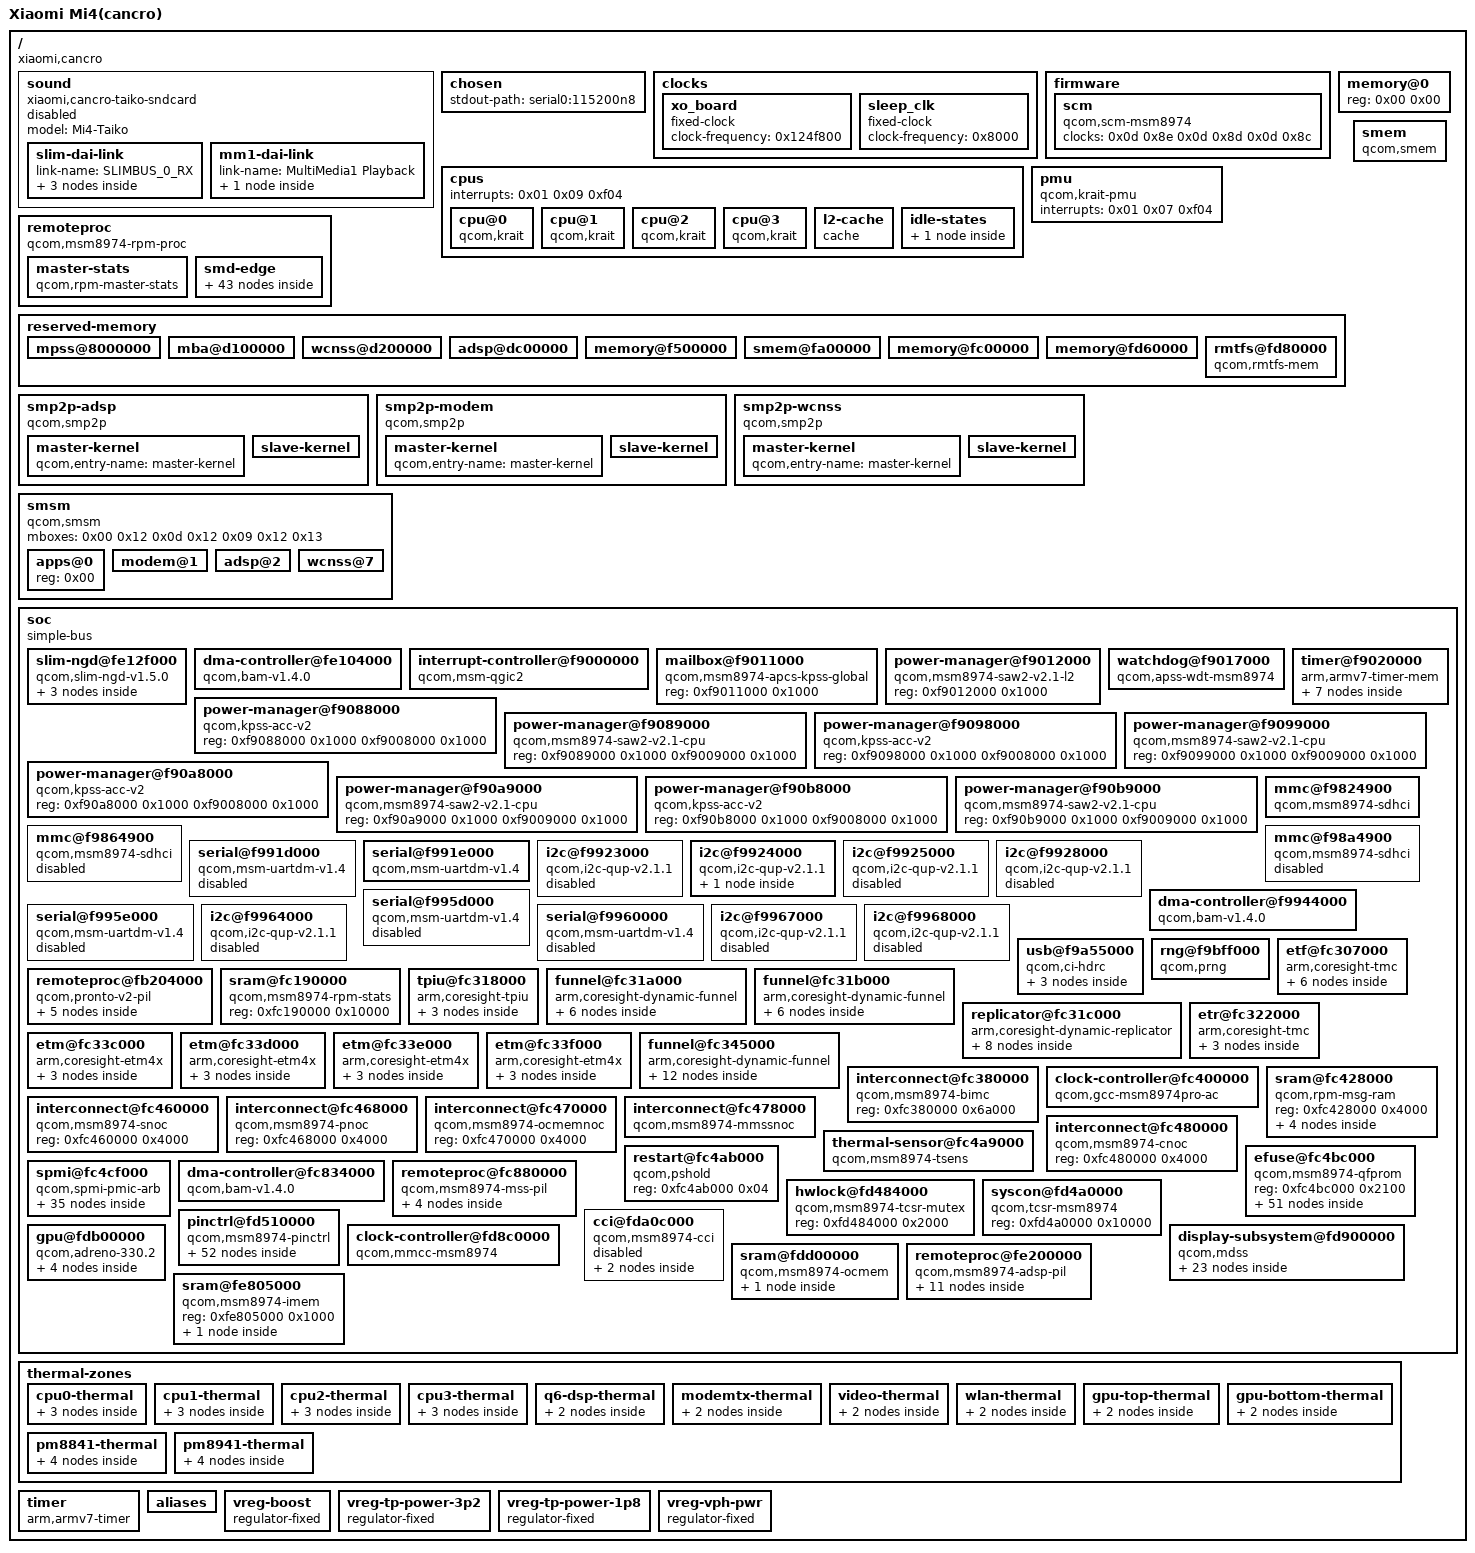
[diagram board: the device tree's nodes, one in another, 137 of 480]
/dts-v1/;

/ {
	#address-cells = <0x01>;
	#size-cells = <0x01>;
	interrupt-parent = <0x01>;
	model = "Xiaomi Mi4(cancro)";
	compatible = "xiaomi,cancro\0qcom,msm8974pro\0qcom,msm8974";
	chassis-type = "handset";
	qcom,msm-id = <0xc2 0x10000>;
	qcom,board-id = <0x08 0x00>;

	__symbols__ {
		mi4_taiko = "/soc/slim-ngd@fe12f000/ngd@1/codec@1,0";
		mi4_slimbam = "/soc/dma-controller@fe104000";
		mi4_q6routing = "/soc/remoteproc@fe200000/smd-edge/apr/service@8/routing";
		mi4_q6asm = "/soc/remoteproc@fe200000/smd-edge/apr/service@7/dais";
		mi4_q6afe = "/soc/remoteproc@fe200000/smd-edge/apr/service@4/dais";
		mi4_audio_l1 = "/remoteproc/smd-edge/rpm-requests/regulators-1/l1/";
	};

	sound {
		status = "disabled";
		model = "Mi4-Taiko";
		compatible = "xiaomi,cancro-taiko-sndcard";

		slim-dai-link {
			link-name = "SLIMBUS_0_RX";

			codec {
				sound-dai = <0xc5>;
			};

			platform {
				sound-dai = <0xc4>;
			};

			cpu {
				sound-dai = <0xc3 0x02>;
			};
		};

		mm1-dai-link {
			link-name = "MultiMedia1 Playback";

			cpu {
				sound-dai = <0xc2 0x00>;
			};
		};
	};

	chosen {
		stdout-path = "serial0:115200n8";
	};

	clocks {

		xo_board {
			compatible = "fixed-clock";
			#clock-cells = <0x00>;
			clock-frequency = <0x124f800>;
			phandle = <0x13>;
		};

		sleep_clk {
			compatible = "fixed-clock";
			#clock-cells = <0x00>;
			clock-frequency = <0x8000>;
			phandle = <0x1d>;
		};
	};

	cpus {
		#address-cells = <0x01>;
		#size-cells = <0x00>;
		interrupts = <0x01 0x09 0xf04>;

		cpu@0 {
			compatible = "qcom,krait";
			enable-method = "qcom,kpss-acc-v2";
			device_type = "cpu";
			reg = <0x00>;
			next-level-cache = <0x02>;
			qcom,acc = <0x03>;
			qcom,saw = <0x04>;
			cpu-idle-states = <0x05>;
			phandle = <0x56>;
		};

		cpu@1 {
			compatible = "qcom,krait";
			enable-method = "qcom,kpss-acc-v2";
			device_type = "cpu";
			reg = <0x01>;
			next-level-cache = <0x02>;
			qcom,acc = <0x06>;
			qcom,saw = <0x07>;
			cpu-idle-states = <0x05>;
			phandle = <0x58>;
		};

		cpu@2 {
			compatible = "qcom,krait";
			enable-method = "qcom,kpss-acc-v2";
			device_type = "cpu";
			reg = <0x02>;
			next-level-cache = <0x02>;
			qcom,acc = <0x08>;
			qcom,saw = <0x09>;
			cpu-idle-states = <0x05>;
			phandle = <0x5a>;
		};

		cpu@3 {
			compatible = "qcom,krait";
			enable-method = "qcom,kpss-acc-v2";
			device_type = "cpu";
			reg = <0x03>;
			next-level-cache = <0x02>;
			qcom,acc = <0x0a>;
			qcom,saw = <0x0b>;
			cpu-idle-states = <0x05>;
			phandle = <0x5c>;
		};

		l2-cache {
			compatible = "cache";
			cache-level = <0x02>;
			cache-unified;
			qcom,saw = <0x0c>;
			phandle = <0x02>;
		};

		idle-states {

			cpu-spc {
				compatible = "qcom,idle-state-spc\0arm,idle-state";
				entry-latency-us = <0x96>;
				exit-latency-us = <0xc8>;
				min-residency-us = <0x7d0>;
				phandle = <0x05>;
			};
		};
	};

	firmware {

		scm {
			compatible = "qcom,scm-msm8974\0qcom,scm";
			clocks = <0x0d 0x8e 0x0d 0x8d 0x0d 0x8c>;
			clock-names = "core\0bus\0iface";
		};
	};

	memory@0 {
		device_type = "memory";
		reg = <0x00 0x00>;
	};

	pmu {
		compatible = "qcom,krait-pmu";
		interrupts = <0x01 0x07 0xf04>;
	};

	remoteproc {
		compatible = "qcom,msm8974-rpm-proc\0qcom,rpm-proc";

		master-stats {
			compatible = "qcom,rpm-master-stats";
			qcom,rpm-msg-ram = <0x0e 0x0f 0x10 0x11>;
			qcom,master-names = "APSS\0MPSS\0LPSS\0PRONTO";
		};

		smd-edge {
			interrupts = <0x00 0xa8 0x01>;
			mboxes = <0x12 0x00>;
			qcom,smd-edge = <0x0f>;

			rpm-requests {
				compatible = "qcom,rpm-msm8974\0qcom,smd-rpm";
				qcom,smd-channels = "rpm_requests";

				clock-controller {
					compatible = "qcom,rpmcc-msm8974\0qcom,rpmcc";
					#clock-cells = <0x01>;
					clocks = <0x13>;
					clock-names = "xo";
					phandle = <0x46>;
				};

				power-controller {
					compatible = "qcom,msm8974-rpmpd";
					#power-domain-cells = <0x01>;
					operating-points-v2 = <0x14>;
					phandle = <0x42>;

					opp-table {
						compatible = "operating-points-v2";
						phandle = <0x14>;

						opp1 {
							opp-level = <0x01>;
						};

						opp2 {
							opp-level = <0x02>;
						};

						opp3 {
							opp-level = <0x03>;
						};

						opp4 {
							opp-level = <0x04>;
						};

						opp5 {
							opp-level = <0x05>;
						};

						opp6 {
							opp-level = <0x06>;
						};
					};
				};

				regulators-0 {
					compatible = "qcom,rpm-pm8841-regulators";

					s1 {
						regulator-min-microvolt = <0xa4cb8>;
						regulator-max-microvolt = <0x100590>;
						phandle = <0x44>;
					};

					s2 {
						regulator-min-microvolt = <0x7a120>;
						regulator-max-microvolt = <0x100590>;
						status = "okay";
					};

					s3 {
						regulator-min-microvolt = <0x100590>;
						regulator-max-microvolt = <0x100590>;
						phandle = <0x9f>;
					};
				};

				regulators-1 {
					compatible = "qcom,rpm-pm8941-regulators";
					vdd_l1_l3-supply = <0x15>;
					vdd_l2_lvs1_2_3-supply = <0x16>;
					vdd_l4_l11-supply = <0x15>;
					vdd_l5_l7-supply = <0x17>;
					vdd_l6_l12_l14_l15-supply = <0x17>;
					vdd_l8_l16_l18_l19-supply = <0x18>;
					vdd_l9_l10_l17_l22-supply = <0x19>;
					vdd_l13_l20_l23_l24-supply = <0x19>;
					vdd_l21-supply = <0x19>;

					s1 {
						regulator-min-microvolt = <0x137478>;
						regulator-max-microvolt = <0x13d620>;
						regulator-always-on;
						regulator-boot-on;
						phandle = <0x15>;
					};

					s2 {
						regulator-min-microvolt = <0x20ce70>;
						regulator-max-microvolt = <0x20ce70>;
						regulator-boot-on;
						phandle = <0x17>;
					};

					s3 {
						regulator-min-microvolt = <0x1b7740>;
						regulator-max-microvolt = <0x1b7740>;
						regulator-system-load = <0x25990>;
						regulator-always-on;
						regulator-boot-on;
						regulator-allow-set-load;
						phandle = <0x16>;
					};

					l1 {
						phandle = <0xc1>;
						regulator-min-microvolt = <0x12b128>;
						regulator-max-microvolt = <0x12b128>;
						regulator-always-on;
						regulator-boot-on;
					};

					l2 {
						regulator-min-microvolt = <0x124f80>;
						regulator-max-microvolt = <0x124f80>;
						regulator-boot-on;
						phandle = <0xac>;
					};

					l3 {
						regulator-min-microvolt = <0x100590>;
						regulator-max-microvolt = <0x12b128>;
						regulator-boot-on;
					};

					l4 {
						regulator-min-microvolt = <0x12b128>;
						regulator-max-microvolt = <0x12b128>;
					};

					l5 {
						regulator-min-microvolt = <0x1b7740>;
						regulator-max-microvolt = <0x1b7740>;
					};

					l6 {
						regulator-min-microvolt = <0x1b7740>;
						regulator-max-microvolt = <0x1b7740>;
						regulator-boot-on;
						phandle = <0x3e>;
					};

					l7 {
						regulator-min-microvolt = <0x1b7740>;
						regulator-max-microvolt = <0x1b7740>;
						regulator-boot-on;
					};

					l8 {
						regulator-min-microvolt = <0x1b7740>;
						regulator-max-microvolt = <0x1b7740>;
					};

					l9 {
						regulator-min-microvolt = <0x1b7740>;
						regulator-max-microvolt = <0x2d0370>;
					};

					l10 {
						regulator-min-microvolt = <0x1b7740>;
						regulator-max-microvolt = <0x2d0370>;
					};

					l11 {
						regulator-min-microvolt = <0x12b128>;
						regulator-max-microvolt = <0x149970>;
						phandle = <0x47>;
					};

					l12 {
						regulator-min-microvolt = <0x1b7740>;
						regulator-max-microvolt = <0x1b7740>;
						regulator-always-on;
						regulator-boot-on;
						regulator-allow-set-load;
						phandle = <0xa0>;
					};

					l13 {
						regulator-min-microvolt = <0x1b7740>;
						regulator-max-microvolt = <0x2d0370>;
						regulator-boot-on;
					};

					l14 {
						regulator-min-microvolt = <0x1b7740>;
						regulator-max-microvolt = <0x1b7740>;
					};

					l15 {
						regulator-min-microvolt = <0x1f47d0>;
						regulator-max-microvolt = <0x1f47d0>;
					};

					l16 {
						regulator-min-microvolt = <0x2932e0>;
						regulator-max-microvolt = <0x2932e0>;
					};

					l17 {
						regulator-min-microvolt = <0x2b7cd0>;
						regulator-max-microvolt = <0x2d0370>;
					};

					l18 {
						regulator-min-microvolt = <0x2b7cd0>;
						regulator-max-microvolt = <0x2b7cd0>;
						regulator-always-on;
					};

					l19 {
						regulator-min-microvolt = <0x2c4020>;
						regulator-max-microvolt = <0x331df0>;
						phandle = <0x48>;
					};

					l20 {
						regulator-min-microvolt = <0x2d0370>;
						regulator-max-microvolt = <0x2d0370>;
						regulator-system-load = <0x30d40>;
						regulator-allow-set-load;
						regulator-boot-on;
						phandle = <0x1e>;
					};

					l21 {
						regulator-min-microvolt = <0x2d0370>;
						regulator-max-microvolt = <0x2d0370>;
						regulator-boot-on;
					};

					l22 {
						regulator-min-microvolt = <0x2dc6c0>;
						regulator-max-microvolt = <0x2dc6c0>;
						regulator-allow-set-load;
						regulator-always-on;
						phandle = <0xad>;
					};

					l23 {
						regulator-min-microvolt = <0x2dc6c0>;
						regulator-max-microvolt = <0x2dc6c0>;
					};

					l24 {
						regulator-min-microvolt = <0x2eebb8>;
						regulator-max-microvolt = <0x2eebb8>;
						phandle = <0x3f>;
					};

					lvs3 {
					};
				};
			};
		};
	};

	reserved-memory {
		#address-cells = <0x01>;
		#size-cells = <0x01>;
		ranges;

		mpss@8000000 {
			reg = <0x8000000 0x5100000>;
			no-map;
			phandle = <0xa2>;
		};

		mba@d100000 {
			reg = <0xd100000 0x100000>;
			no-map;
			phandle = <0xa1>;
		};

		wcnss@d200000 {
			reg = <0xd200000 0xa00000>;
			no-map;
			phandle = <0x40>;
		};

		adsp@dc00000 {
			reg = <0xdc00000 0x1900000>;
			no-map;
			phandle = <0xba>;
		};

		memory@f500000 {
			reg = <0xf500000 0x500000>;
			no-map;
		};

		smem@fa00000 {
			reg = <0xfa00000 0x200000>;
			no-map;
			phandle = <0x1a>;
		};

		memory@fc00000 {
			reg = <0xfc00000 0x160000>;
			no-map;
		};

		memory@fd60000 {
			reg = <0xfd60000 0x20000>;
			no-map;
		};

		rmtfs@fd80000 {
			compatible = "qcom,rmtfs-mem";
			reg = <0xfd80000 0x180000>;
			no-map;
			qcom,client-id = <0x01>;
		};
	};

	smem {
		compatible = "qcom,smem";
		memory-region = <0x1a>;
		qcom,rpm-msg-ram = <0x1b>;
		hwlocks = <0x1c 0x03>;
	};

	smp2p-adsp {
		compatible = "qcom,smp2p";
		qcom,smem = <0x1bb 0x1ad>;
		interrupt-parent = <0x01>;
		interrupts = <0x00 0x9e 0x01>;
		mboxes = <0x12 0x0a>;
		qcom,local-pid = <0x00>;
		qcom,remote-pid = <0x02>;

		master-kernel {
			qcom,entry-name = "master-kernel";
			#qcom,smem-state-cells = <0x01>;
			phandle = <0xbb>;
		};

		slave-kernel {
			qcom,entry-name = "slave-kernel";
			interrupt-controller;
			#interrupt-cells = <0x02>;
			phandle = <0xb9>;
		};
	};

	smp2p-modem {
		compatible = "qcom,smp2p";
		qcom,smem = <0x1b3 0x1ac>;
		interrupt-parent = <0x01>;
		interrupts = <0x00 0x1b 0x01>;
		mboxes = <0x12 0x0e>;
		qcom,local-pid = <0x00>;
		qcom,remote-pid = <0x01>;

		master-kernel {
			qcom,entry-name = "master-kernel";
			#qcom,smem-state-cells = <0x01>;
			phandle = <0x9e>;
		};

		slave-kernel {
			qcom,entry-name = "slave-kernel";
			interrupt-controller;
			#interrupt-cells = <0x02>;
			phandle = <0x9d>;
		};
	};

	smp2p-wcnss {
		compatible = "qcom,smp2p";
		qcom,smem = <0x1c3 0x1af>;
		interrupt-parent = <0x01>;
		interrupts = <0x00 0x8f 0x01>;
		mboxes = <0x12 0x12>;
		qcom,local-pid = <0x00>;
		qcom,remote-pid = <0x04>;

		master-kernel {
			qcom,entry-name = "master-kernel";
			#qcom,smem-state-cells = <0x01>;
			phandle = <0x43>;
		};

		slave-kernel {
			qcom,entry-name = "slave-kernel";
			interrupt-controller;
			#interrupt-cells = <0x02>;
			phandle = <0x41>;
		};
	};

	smsm {
		compatible = "qcom,smsm";
		#address-cells = <0x01>;
		#size-cells = <0x00>;
		mboxes = <0x00 0x12 0x0d 0x12 0x09 0x12 0x13>;

		apps@0 {
			reg = <0x00>;
			#qcom,smem-state-cells = <0x01>;
			phandle = <0x4a>;
		};

		modem@1 {
			reg = <0x01>;
			interrupts = <0x00 0x1a 0x01>;
			interrupt-controller;
			#interrupt-cells = <0x02>;
			phandle = <0xa3>;
		};

		adsp@2 {
			reg = <0x02>;
			interrupts = <0x00 0x9d 0x01>;
			interrupt-controller;
			#interrupt-cells = <0x02>;
		};

		wcnss@7 {
			reg = <0x07>;
			interrupts = <0x00 0x90 0x01>;
			interrupt-controller;
			#interrupt-cells = <0x02>;
		};
	};

	soc {
		#address-cells = <0x01>;
		#size-cells = <0x01>;
		ranges;
		compatible = "simple-bus";

		slim-ngd@fe12f000 {
			#size-cells = <0x00>;
			#address-cells = <0x01>;
			dma-names = "rx\0tx";
			dmas = <0xc0 0x03 0xc0 0x04>;
			interrupts = <0x00 0xa3 0x04>;
			interrupt-parent = <0x01>;
			reg = <0xfe12f000 0x35000>;
			compatible = "qcom,slim-ngd-v1.5.0";

			ngd@1 {
				#size-cells = <0x00>;
				#address-cells = <0x02>;
				reg = <0x01>;

				codec@1,0 {
					phandle = <0xc5>;
					vddcx-2-supply = <0xc1>;
					vddcx-1-supply = <0xc1>;
					vdd-a-1p2v-supply = <0xc1>;
					vddpx-1-supply = <0x16>;
					vdd-rx-h-supply = <0x16>;
					vdd-tx-h-supply = <0x16>;
					vdd-buck-supply = <0x17>;
					irq-gpios = <0x26 0x48 0x00>;
					interrupts-extended = <0x26 0x48 0x04>;
					reset-gpios = <0x26 0x3f 0x01>;
					#sound-dai-cells = <0x00>;
					reg = <0x01 0x00>;
					compatible = "slim217,a0";
				};

				codec@0,0 {
					reg = <0x00 0x00>;
					compatible = "slim217,a0";
				};
			};
		};

		dma-controller@fe104000 {
			phandle = <0xc0>;
			qcom,num-ees = <0x02>;
			qcom,ee = <0x01>;
			#dma-cells = <0x01>;
			num-channels = <0x1f>;
			interrupts = <0x00 0xa4 0x04>;
			interrupt-parent = <0x01>;
			reg = <0xfe104000 0x20000>;
			qcom,controlled-remotely;
			compatible = "qcom,bam-v1.4.0";
		};

		interrupt-controller@f9000000 {
			compatible = "qcom,msm-qgic2";
			interrupt-controller;
			#interrupt-cells = <0x03>;
			reg = <0xf9000000 0x1000 0xf9002000 0x1000>;
			phandle = <0x01>;
		};

		mailbox@f9011000 {
			compatible = "qcom,msm8974-apcs-kpss-global\0qcom,msm8994-apcs-kpss-global\0syscon";
			reg = <0xf9011000 0x1000>;
			#mbox-cells = <0x01>;
			phandle = <0x12>;
		};

		power-manager@f9012000 {
			compatible = "qcom,msm8974-saw2-v2.1-l2\0qcom,saw2";
			reg = <0xf9012000 0x1000>;
			phandle = <0x0c>;
		};

		watchdog@f9017000 {
			compatible = "qcom,apss-wdt-msm8974\0qcom,kpss-wdt";
			reg = <0xf9017000 0x1000>;
			interrupts = <0x00 0x03 0x01 0x00 0x04 0x01>;
			clocks = <0x1d>;
		};

		timer@f9020000 {
			#address-cells = <0x01>;
			#size-cells = <0x01>;
			ranges;
			compatible = "arm,armv7-timer-mem";
			reg = <0xf9020000 0x1000>;
			clock-frequency = <0x124f800>;

			frame@f9021000 {
				frame-number = <0x00>;
				interrupts = <0x00 0x08 0x04 0x00 0x07 0x04>;
				reg = <0xf9021000 0x1000 0xf9022000 0x1000>;
			};

			frame@f9023000 {
				frame-number = <0x01>;
				interrupts = <0x00 0x09 0x04>;
				reg = <0xf9023000 0x1000>;
				status = "disabled";
			};

			frame@f9024000 {
				frame-number = <0x02>;
				interrupts = <0x00 0x0a 0x04>;
				reg = <0xf9024000 0x1000>;
				status = "disabled";
			};

			frame@f9025000 {
				frame-number = <0x03>;
				interrupts = <0x00 0x0b 0x04>;
				reg = <0xf9025000 0x1000>;
				status = "disabled";
			};

			frame@f9026000 {
				frame-number = <0x04>;
				interrupts = <0x00 0x0c 0x04>;
				reg = <0xf9026000 0x1000>;
				status = "disabled";
			};

			frame@f9027000 {
				frame-number = <0x05>;
				interrupts = <0x00 0x0d 0x04>;
				reg = <0xf9027000 0x1000>;
				status = "disabled";
			};

			frame@f9028000 {
				frame-number = <0x06>;
				interrupts = <0x00 0x0e 0x04>;
				reg = <0xf9028000 0x1000>;
				status = "disabled";
			};
		};

		power-manager@f9088000 {
			compatible = "qcom,kpss-acc-v2";
			reg = <0xf9088000 0x1000 0xf9008000 0x1000>;
			phandle = <0x03>;
		};

		power-manager@f9089000 {
			compatible = "qcom,msm8974-saw2-v2.1-cpu\0qcom,saw2";
			reg = <0xf9089000 0x1000 0xf9009000 0x1000>;
			phandle = <0x04>;
		};

		power-manager@f9098000 {
			compatible = "qcom,kpss-acc-v2";
			reg = <0xf9098000 0x1000 0xf9008000 0x1000>;
			phandle = <0x06>;
		};

		power-manager@f9099000 {
			compatible = "qcom,msm8974-saw2-v2.1-cpu\0qcom,saw2";
			reg = <0xf9099000 0x1000 0xf9009000 0x1000>;
			phandle = <0x07>;
		};

		power-manager@f90a8000 {
			compatible = "qcom,kpss-acc-v2";
			reg = <0xf90a8000 0x1000 0xf9008000 0x1000>;
			phandle = <0x08>;
		};

		power-manager@f90a9000 {
			compatible = "qcom,msm8974-saw2-v2.1-cpu\0qcom,saw2";
			reg = <0xf90a9000 0x1000 0xf9009000 0x1000>;
			phandle = <0x09>;
		};

		power-manager@f90b8000 {
			compatible = "qcom,kpss-acc-v2";
			reg = <0xf90b8000 0x1000 0xf9008000 0x1000>;
			phandle = <0x0a>;
		};

		power-manager@f90b9000 {
			compatible = "qcom,msm8974-saw2-v2.1-cpu\0qcom,saw2";
			reg = <0xf90b9000 0x1000 0xf9009000 0x1000>;
			phandle = <0x0b>;
		};

		mmc@f9824900 {
			compatible = "qcom,msm8974-sdhci\0qcom,sdhci-msm-v4";
			reg = <0xf9824900 0x11c 0xf9824000 0x800>;
			reg-names = "hc\0core";
			interrupts = <0x00 0x7b 0x04 0x00 0x8a 0x04>;
			interrupt-names = "hc_irq\0pwr_irq";
			clocks = <0x0d 0xd7 0x0d 0xd8 0x13 0x0d 0x131 0x0d 0x130>;
			clock-names = "iface\0core\0xo\0cal\0sleep";
			bus-width = <0x08>;
			non-removable;
			status = "okay";
			vmmc-supply = <0x1e>;
			vqmmc-supply = <0x16>;
			pinctrl-names = "default\0sleep";
			pinctrl-0 = <0x1f>;
			pinctrl-1 = <0x20>;
		};

		mmc@f9864900 {
			compatible = "qcom,msm8974-sdhci\0qcom,sdhci-msm-v4";
			reg = <0xf9864900 0x11c 0xf9864000 0x800>;
			reg-names = "hc\0core";
			interrupts = <0x00 0x7f 0x04 0x00 0xe0 0x04>;
			interrupt-names = "hc_irq\0pwr_irq";
			clocks = <0x0d 0xdd 0x0d 0xde 0x13>;
			clock-names = "iface\0core\0xo";
			bus-width = <0x04>;
			#address-cells = <0x01>;
			#size-cells = <0x00>;
			status = "disabled";
		};

		mmc@f98a4900 {
			compatible = "qcom,msm8974-sdhci\0qcom,sdhci-msm-v4";
			reg = <0xf98a4900 0x11c 0xf98a4000 0x800>;
			reg-names = "hc\0core";
			interrupts = <0x00 0x7d 0x04 0x00 0xdd 0x04>;
			interrupt-names = "hc_irq\0pwr_irq";
			clocks = <0x0d 0xda 0x0d 0xdb 0x13>;
			clock-names = "iface\0core\0xo";
			bus-width = <0x04>;
			#address-cells = <0x01>;
			#size-cells = <0x00>;
			status = "disabled";
		};

		serial@f991d000 {
			compatible = "qcom,msm-uartdm-v1.4\0qcom,msm-uartdm";
			reg = <0xf991d000 0x1000>;
			interrupts = <0x00 0x6b 0x04>;
			clocks = <0x0d 0x65 0x0d 0x57>;
			clock-names = "core\0iface";
			status = "disabled";
		};

		serial@f991e000 {
			compatible = "qcom,msm-uartdm-v1.4\0qcom,msm-uartdm";
			reg = <0xf991e000 0x1000>;
			interrupts = <0x00 0x6c 0x04>;
			clocks = <0x0d 0x67 0x0d 0x57>;
			clock-names = "core\0iface";
			pinctrl-names = "default";
			pinctrl-0 = <0x21>;
			status = "okay";
		};

		i2c@f9923000 {
			status = "disabled";
			compatible = "qcom,i2c-qup-v2.1.1";
			reg = <0xf9923000 0x1000>;
			interrupts = <0x00 0x5f 0x04>;
			clocks = <0x0d 0x59 0x0d 0x57>;
			clock-names = "core\0iface";
			pinctrl-names = "default\0sleep";
			pinctrl-0 = <0x22>;
			pinctrl-1 = <0x23>;
			#address-cells = <0x01>;
			#size-cells = <0x00>;
		};

		i2c@f9924000 {
			status = "okay";
			compatible = "qcom,i2c-qup-v2.1.1";
			reg = <0xf9924000 0x1000>;
			interrupts = <0x00 0x60 0x04>;
			clocks = <0x0d 0x5b 0x0d 0x57>;
			clock-names = "core\0iface";
			pinctrl-names = "default\0sleep";
			pinctrl-0 = <0x24>;
			pinctrl-1 = <0x25>;
			#address-cells = <0x01>;
			#size-cells = <0x00>;

			touchscreen@4a {
				compatible = "atmel,maxtouch";
				reg = <0x4a>;
				status = "okay";
				interrupts-extended = <0x26 0x36 0x02>;
				linux,keycodes = <0x00 0x244 0x9e>;
				pinctrl-names = "default";
				pinctrl-0 = <0x27>;
				reset-gpios = <0x26 0x3c 0x01>;
				vdd-supply = <0x28>;
				vdda-supply = <0x29>;
			};
		};

		i2c@f9925000 {
			status = "disabled";
			compatible = "qcom,i2c-qup-v2.1.1";
			reg = <0xf9925000 0x1000>;
			interrupts = <0x00 0x61 0x04>;
			clocks = <0x0d 0x5d 0x0d 0x57>;
			clock-names = "core\0iface";
			pinctrl-names = "default\0sleep";
			pinctrl-0 = <0x2a>;
			pinctrl-1 = <0x2b>;
			#address-cells = <0x01>;
			#size-cells = <0x00>;
		};

		i2c@f9928000 {
			status = "disabled";
			compatible = "qcom,i2c-qup-v2.1.1";
			reg = <0xf9928000 0x1000>;
			interrupts = <0x00 0x64 0x04>;
			clocks = <0x0d 0x63 0x0d 0x57>;
			clock-names = "core\0iface";
			pinctrl-names = "default\0sleep";
			pinctrl-0 = <0x2c>;
			pinctrl-1 = <0x2d>;
			#address-cells = <0x01>;
			#size-cells = <0x00>;
		};

		dma-controller@f9944000 {
			compatible = "qcom,bam-v1.4.0";
			reg = <0xf9944000 0x19000>;
			interrupts = <0x00 0xef 0x04>;
			clocks = <0x0d 0x71>;
			clock-names = "bam_clk";
			#dma-cells = <0x01>;
			qcom,ee = <0x00>;
			phandle = <0x33>;
		};

		serial@f995d000 {
			compatible = "qcom,msm-uartdm-v1.4\0qcom,msm-uartdm";
			reg = <0xf995d000 0x1000>;
			interrupts = <0x00 0x71 0x04>;
			clocks = <0x0d 0x7f 0x0d 0x71>;
			clock-names = "core\0iface";
			pinctrl-names = "default\0sleep";
			pinctrl-0 = <0x2e>;
			pinctrl-1 = <0x2f>;
			status = "disabled";
		};

		serial@f995e000 {
			compatible = "qcom,msm-uartdm-v1.4\0qcom,msm-uartdm";
			reg = <0xf995e000 0x1000>;
			interrupts = <0x00 0x72 0x04>;
			clocks = <0x0d 0x81 0x0d 0x71>;
			clock-names = "core\0iface";
			status = "disabled";
		};

		serial@f9960000 {
			compatible = "qcom,msm-uartdm-v1.4\0qcom,msm-uartdm";
			reg = <0xf9960000 0x1000>;
			interrupts = <0x00 0x74 0x04>;
			clocks = <0x0d 0x85 0x0d 0x71>;
			clock-names = "core\0iface";
			pinctrl-names = "default";
			pinctrl-0 = <0x30>;
			status = "disabled";
		};

		i2c@f9964000 {
			status = "disabled";
			compatible = "qcom,i2c-qup-v2.1.1";
			reg = <0xf9964000 0x1000>;
			interrupts = <0x00 0x66 0x04>;
			clocks = <0x0d 0x75 0x0d 0x71>;
			clock-names = "core\0iface";
			pinctrl-names = "default\0sleep";
			pinctrl-0 = <0x31>;
			pinctrl-1 = <0x32>;
			#address-cells = <0x01>;
			#size-cells = <0x00>;
		};

		i2c@f9967000 {
			status = "disabled";
			compatible = "qcom,i2c-qup-v2.1.1";
			reg = <0xf9967000 0x1000>;
			interrupts = <0x00 0x69 0x04>;
			clocks = <0x0d 0x7b 0x0d 0x71>;
			clock-names = "core\0iface";
			dmas = <0x33 0x14 0x33 0x15>;
			dma-names = "tx\0rx";
			pinctrl-names = "default\0sleep";
			pinctrl-0 = <0x34>;
			pinctrl-1 = <0x35>;
			#address-cells = <0x01>;
			#size-cells = <0x00>;
		};

		i2c@f9968000 {
			status = "disabled";
			compatible = "qcom,i2c-qup-v2.1.1";
			reg = <0xf9968000 0x1000>;
			interrupts = <0x00 0x6a 0x04>;
			clocks = <0x0d 0x7d 0x0d 0x71>;
			clock-names = "core\0iface";
			pinctrl-names = "default\0sleep";
			pinctrl-0 = <0x36>;
			pinctrl-1 = <0x37>;
			#address-cells = <0x01>;
			#size-cells = <0x00>;
		};

		usb@f9a55000 {
			compatible = "qcom,ci-hdrc";
			reg = <0xf9a55000 0x200 0xf9a55200 0x200>;
			interrupts = <0x00 0x86 0x04>;
			clocks = <0x0d 0x107 0x0d 0x109>;
			clock-names = "iface\0core";
			assigned-clocks = <0x0d 0x109>;
			assigned-clock-rates = <0x47868c0>;
			resets = <0x0d 0x09>;
			reset-names = "core";
			phy_type = "ulpi";
			dr_mode = "otg";
			ahb-burst-config = <0x00>;
			phy-names = "usb-phy";
			status = "okay";
			#reset-cells = <0x01>;
			phys = <0x38>;
			phy-select = <0x39 0xb000 0x00>;
			extcon = <0x3a 0x3b>;
			vbus-supply = <0x3c>;
			hnp-disable;
			srp-disable;
			adp-disable;
			phandle = <0x3d>;

			ulpi {

				phy-0 {
					compatible = "qcom,usb-hs-phy-msm8974\0qcom,usb-hs-phy";
					#phy-cells = <0x00>;
					clocks = <0x13 0x0d 0x102>;
					clock-names = "ref\0sleep";
					resets = <0x0d 0x0a 0x3d 0x00>;
					reset-names = "phy\0por";
					status = "okay";
					v1p8-supply = <0x3e>;
					v3p3-supply = <0x3f>;
					extcon = <0x3a>;
					qcom,init-seq = [01 64];
					phandle = <0x38>;
				};

				phy-1 {
					compatible = "qcom,usb-hs-phy-msm8974\0qcom,usb-hs-phy";
					#phy-cells = <0x00>;
					clocks = <0x13 0x0d 0x103>;
					clock-names = "ref\0sleep";
					resets = <0x0d 0x0b 0x3d 0x01>;
					reset-names = "phy\0por";
					status = "disabled";
				};
			};
		};

		rng@f9bff000 {
			compatible = "qcom,prng";
			reg = <0xf9bff000 0x200>;
			clocks = <0x0d 0xc3>;
			clock-names = "core";
		};

		remoteproc@fb204000 {
			compatible = "qcom,pronto-v2-pil\0qcom,pronto";
			reg = <0xfb204000 0x2000 0xfb202000 0x1000 0xfb21b000 0x3000>;
			reg-names = "ccu\0dxe\0pmu";
			memory-region = <0x40>;
			interrupts-extended = <0x01 0x00 0x95 0x01 0x41 0x00 0x01 0x41 0x01 0x01 0x41 0x02 0x01 0x41 0x03 0x01>;
			interrupt-names = "wdog\0fatal\0ready\0handover\0stop-ack";
			power-domains = <0x42 0x00>;
			power-domain-names = "cx";
			qcom,smem-states = <0x43 0x00>;
			qcom,smem-state-names = "stop";
			status = "okay";
			vddmx-supply = <0x44>;
			vddpx-supply = <0x16>;
			pinctrl-names = "default";
			pinctrl-0 = <0x45>;
			phandle = <0x49>;

			iris {
				compatible = "qcom,wcn3680";
				clocks = <0x46 0x2c>;
				clock-names = "xo";
				vddxo-supply = <0x3e>;
				vddrfa-supply = <0x47>;
				vddpa-supply = <0x48>;
				vdddig-supply = <0x16>;
			};

			smd-edge {
				interrupts = <0x00 0x8e 0x01>;
				mboxes = <0x12 0x11>;
				qcom,smd-edge = <0x06>;
				qcom,remote-pid = <0x04>;
				label = "pronto";

				wcnss {
					compatible = "qcom,wcnss";
					qcom,smd-channels = "WCNSS_CTRL";
					status = "okay";
					qcom,mmio = <0x49>;

					bluetooth {
						compatible = "qcom,wcnss-bt";
					};

					wifi {
						compatible = "qcom,wcnss-wlan";
						interrupts = <0x00 0x91 0x01 0x00 0x92 0x01>;
						interrupt-names = "tx\0rx";
						qcom,smem-states = <0x4a 0x0a 0x4a 0x09>;
						qcom,smem-state-names = "tx-enable\0tx-rings-empty";
					};
				};
			};
		};

		sram@fc190000 {
			compatible = "qcom,msm8974-rpm-stats";
			reg = <0xfc190000 0x10000>;
		};

		etf@fc307000 {
			compatible = "arm,coresight-tmc\0arm,primecell";
			reg = <0xfc307000 0x1000>;
			clocks = <0x46 0x08 0x46 0x09>;
			clock-names = "apb_pclk\0atclk";

			out-ports {

				port {

					endpoint {
						remote-endpoint = <0x4b>;
						phandle = <0x54>;
					};
				};
			};

			in-ports {

				port {

					endpoint {
						remote-endpoint = <0x4c>;
						phandle = <0x51>;
					};
				};
			};
		};

		tpiu@fc318000 {
			compatible = "arm,coresight-tpiu\0arm,primecell";
			reg = <0xfc318000 0x1000>;
			clocks = <0x46 0x08 0x46 0x09>;
			clock-names = "apb_pclk\0atclk";

			in-ports {

				port {

					endpoint {
						remote-endpoint = <0x4d>;
						phandle = <0x53>;
					};
				};
			};
		};

		funnel@fc31a000 {
			compatible = "arm,coresight-dynamic-funnel\0arm,primecell";
			reg = <0xfc31a000 0x1000>;
			clocks = <0x46 0x08 0x46 0x09>;
			clock-names = "apb_pclk\0atclk";

			in-ports {
				#address-cells = <0x01>;
				#size-cells = <0x00>;

				port@5 {
					reg = <0x05>;

					endpoint {
						remote-endpoint = <0x4e>;
						phandle = <0x62>;
					};
				};
			};

			out-ports {

				port {

					endpoint {
						remote-endpoint = <0x4f>;
						phandle = <0x50>;
					};
				};
			};
		};

		funnel@fc31b000 {
			compatible = "arm,coresight-dynamic-funnel\0arm,primecell";
			reg = <0xfc31b000 0x1000>;
			clocks = <0x46 0x08 0x46 0x09>;
			clock-names = "apb_pclk\0atclk";

			in-ports {
				#address-cells = <0x01>;
				#size-cells = <0x00>;

				port@1 {
					reg = <0x01>;

					endpoint {
						remote-endpoint = <0x50>;
						phandle = <0x4f>;
					};
				};
			};

			out-ports {

				port {

					endpoint {
						remote-endpoint = <0x51>;
						phandle = <0x4c>;
					};
				};
			};
		};

		replicator@fc31c000 {
			compatible = "arm,coresight-dynamic-replicator\0arm,primecell";
			reg = <0xfc31c000 0x1000>;
			clocks = <0x46 0x08 0x46 0x09>;
			clock-names = "apb_pclk\0atclk";

			out-ports {
				#address-cells = <0x01>;
				#size-cells = <0x00>;

				port@0 {
					reg = <0x00>;

					endpoint {
						remote-endpoint = <0x52>;
						phandle = <0x55>;
					};
				};

				port@1 {
					reg = <0x01>;

					endpoint {
						remote-endpoint = <0x53>;
						phandle = <0x4d>;
					};
				};
			};

			in-ports {

				port {

					endpoint {
						remote-endpoint = <0x54>;
						phandle = <0x4b>;
					};
				};
			};
		};

		etr@fc322000 {
			compatible = "arm,coresight-tmc\0arm,primecell";
			reg = <0xfc322000 0x1000>;
			clocks = <0x46 0x08 0x46 0x09>;
			clock-names = "apb_pclk\0atclk";

			in-ports {

				port {

					endpoint {
						remote-endpoint = <0x55>;
						phandle = <0x52>;
					};
				};
			};
		};

		etm@fc33c000 {
			compatible = "arm,coresight-etm4x\0arm,primecell";
			reg = <0xfc33c000 0x1000>;
			clocks = <0x46 0x08 0x46 0x09>;
			clock-names = "apb_pclk\0atclk";
			cpu = <0x56>;

			out-ports {

				port {

					endpoint {
						remote-endpoint = <0x57>;
						phandle = <0x5e>;
					};
				};
			};
		};

		etm@fc33d000 {
			compatible = "arm,coresight-etm4x\0arm,primecell";
			reg = <0xfc33d000 0x1000>;
			clocks = <0x46 0x08 0x46 0x09>;
			clock-names = "apb_pclk\0atclk";
			cpu = <0x58>;

			out-ports {

				port {

					endpoint {
						remote-endpoint = <0x59>;
						phandle = <0x5f>;
					};
				};
			};
		};

		etm@fc33e000 {
			compatible = "arm,coresight-etm4x\0arm,primecell";
			reg = <0xfc33e000 0x1000>;
			clocks = <0x46 0x08 0x46 0x09>;
			clock-names = "apb_pclk\0atclk";
			cpu = <0x5a>;

			out-ports {

				port {

					endpoint {
						remote-endpoint = <0x5b>;
						phandle = <0x60>;
					};
				};
			};
		};

		etm@fc33f000 {
			compatible = "arm,coresight-etm4x\0arm,primecell";
			reg = <0xfc33f000 0x1000>;
			clocks = <0x46 0x08 0x46 0x09>;
			clock-names = "apb_pclk\0atclk";
			cpu = <0x5c>;

			out-ports {

				port {

					endpoint {
						remote-endpoint = <0x5d>;
						phandle = <0x61>;
					};
				};
			};
		};

		funnel@fc345000 {
			compatible = "arm,coresight-dynamic-funnel\0arm,primecell";
			reg = <0xfc345000 0x1000>;
			clocks = <0x46 0x08 0x46 0x09>;
			clock-names = "apb_pclk\0atclk";

			in-ports {
				#address-cells = <0x01>;
				#size-cells = <0x00>;

				port@0 {
					reg = <0x00>;

					endpoint {
						remote-endpoint = <0x5e>;
						phandle = <0x57>;
					};
				};

				port@1 {
					reg = <0x01>;

					endpoint {
						remote-endpoint = <0x5f>;
						phandle = <0x59>;
					};
				};

				port@2 {
					reg = <0x02>;

					endpoint {
						remote-endpoint = <0x60>;
						phandle = <0x5b>;
					};
				};

				port@3 {
					reg = <0x03>;

					endpoint {
						remote-endpoint = <0x61>;
						phandle = <0x5d>;
					};
				};
			};

			out-ports {

				port {

					endpoint {
						remote-endpoint = <0x62>;
						phandle = <0x4e>;
					};
				};
			};
		};

		interconnect@fc380000 {
			reg = <0xfc380000 0x6a000>;
			compatible = "qcom,msm8974-bimc";
			#interconnect-cells = <0x01>;
			phandle = <0xa9>;
		};

		clock-controller@fc400000 {
			compatible = "qcom,gcc-msm8974pro-ac";
			#clock-cells = <0x01>;
			#reset-cells = <0x01>;
			#power-domain-cells = <0x01>;
			reg = <0xfc400000 0x4000>;
			clocks = <0x46 0x00 0x1d>;
			clock-names = "xo\0sleep_clk";
			phandle = <0x0d>;
		};

		sram@fc428000 {
			compatible = "qcom,rpm-msg-ram";
			reg = <0xfc428000 0x4000>;
			#address-cells = <0x01>;
			#size-cells = <0x01>;
			ranges = <0x00 0xfc428000 0x4000>;
			phandle = <0x1b>;

			sram@150 {
				reg = <0x150 0x14>;
				phandle = <0x0e>;
			};

			sram@b50 {
				reg = <0xb50 0x14>;
				phandle = <0x0f>;
			};

			sram@1550 {
				reg = <0x1550 0x14>;
				phandle = <0x10>;
			};

			sram@1f50 {
				reg = <0x1f50 0x14>;
				phandle = <0x11>;
			};
		};

		interconnect@fc460000 {
			reg = <0xfc460000 0x4000>;
			compatible = "qcom,msm8974-snoc";
			#interconnect-cells = <0x01>;
		};

		interconnect@fc468000 {
			reg = <0xfc468000 0x4000>;
			compatible = "qcom,msm8974-pnoc";
			#interconnect-cells = <0x01>;
		};

		interconnect@fc470000 {
			reg = <0xfc470000 0x4000>;
			compatible = "qcom,msm8974-ocmemnoc";
			#interconnect-cells = <0x01>;
			phandle = <0xb8>;
		};

		interconnect@fc478000 {
			reg = <0xfc478000 0x4000>;
			compatible = "qcom,msm8974-mmssnoc";
			#interconnect-cells = <0x01>;
			clocks = <0x63 0x72>;
			clock-names = "bus";
			phandle = <0xa8>;
		};

		interconnect@fc480000 {
			reg = <0xfc480000 0x4000>;
			compatible = "qcom,msm8974-cnoc";
			#interconnect-cells = <0x01>;
		};

		thermal-sensor@fc4a9000 {
			compatible = "qcom,msm8974-tsens\0qcom,tsens-v0_1";
			reg = <0xfc4a9000 0x1000 0xfc4a8000 0x1000>;
			nvmem-cells = <0x64 0x65 0x66 0x67 0x68 0x69 0x6a 0x6b 0x6c 0x6d 0x6e 0x6f 0x70 0x71 0x72 0x73 0x74 0x75 0x76 0x77 0x78 0x79 0x7a 0x7b 0x7c 0x7d 0x7e 0x7f 0x80 0x81 0x82 0x83 0x84 0x85 0x86 0x87 0x88 0x89 0x8a 0x8b 0x8c 0x8d 0x8e 0x8f 0x90 0x91 0x92 0x93 0x94 0x95 0x96>;
			nvmem-cell-names = "mode\0base1\0base2\0use_backup\0mode_backup\0base1_backup\0base2_backup\0s0_p1\0s0_p2\0s1_p1\0s1_p2\0s2_p1\0s2_p2\0s3_p1\0s3_p2\0s4_p1\0s4_p2\0s5_p1\0s5_p2\0s6_p1\0s6_p2\0s7_p1\0s7_p2\0s8_p1\0s8_p2\0s9_p1\0s9_p2\0s10_p1\0s10_p2\0s0_p1_backup\0s0_p2_backup\0s1_p1_backup\0s1_p2_backup\0s2_p1_backup\0s2_p2_backup\0s3_p1_backup\0s3_p2_backup\0s4_p1_backup\0s4_p2_backup\0s5_p1_backup\0s5_p2_backup\0s6_p1_backup\0s6_p2_backup\0s7_p1_backup\0s7_p2_backup\0s8_p1_backup\0s8_p2_backup\0s9_p1_backup\0s9_p2_backup\0s10_p1_backup\0s10_p2_backup";
			#qcom,sensors = <0x0b>;
			interrupts = <0x00 0xb8 0x04>;
			interrupt-names = "uplow";
			#thermal-sensor-cells = <0x01>;
			phandle = <0xbc>;
		};

		restart@fc4ab000 {
			compatible = "qcom,pshold";
			reg = <0xfc4ab000 0x04>;
		};

		efuse@fc4bc000 {
			compatible = "qcom,msm8974-qfprom\0qcom,qfprom";
			reg = <0xfc4bc000 0x2100>;
			#address-cells = <0x01>;
			#size-cells = <0x01>;

			base1@d0 {
				reg = <0xd0 0x01>;
				bits = <0x00 0x08>;
				phandle = <0x65>;
			};

			s0-p1@d1 {
				reg = <0xd1 0x01>;
				bits = <0x00 0x06>;
				phandle = <0x6b>;
			};

			s1-p1@d2 {
				reg = <0xd1 0x02>;
				bits = <0x06 0x06>;
				phandle = <0x6d>;
			};

			s2-p1@d2 {
				reg = <0xd2 0x02>;
				bits = <0x04 0x06>;
				phandle = <0x6f>;
			};

			s3-p1@d3 {
				reg = <0xd3 0x01>;
				bits = <0x02 0x06>;
				phandle = <0x71>;
			};

			s4-p1@d4 {
				reg = <0xd4 0x01>;
				bits = <0x00 0x06>;
				phandle = <0x73>;
			};

			s5-p1@d4 {
				reg = <0xd4 0x02>;
				bits = <0x06 0x06>;
				phandle = <0x75>;
			};

			s6-p1@d5 {
				reg = <0xd5 0x02>;
				bits = <0x04 0x06>;
				phandle = <0x77>;
			};

			s7-p1@d6 {
				reg = <0xd6 0x01>;
				bits = <0x02 0x06>;
				phandle = <0x79>;
			};

			s8-p1@d7 {
				reg = <0xd7 0x01>;
				bits = <0x00 0x06>;
				phandle = <0x7b>;
			};

			mode@d7 {
				reg = <0xd7 0x01>;
				bits = <0x06 0x02>;
				phandle = <0x64>;
			};

			s9-p1@d8 {
				reg = <0xd8 0x01>;
				bits = <0x00 0x06>;
				phandle = <0x7d>;
			};

			s10-p1@d8 {
				reg = <0xd8 0x02>;
				bits = <0x06 0x06>;
				phandle = <0x7f>;
			};

			base2@d9 {
				reg = <0xd9 0x02>;
				bits = <0x04 0x08>;
				phandle = <0x66>;
			};

			s0-p2@da {
				reg = <0xda 0x02>;
				bits = <0x04 0x06>;
				phandle = <0x6c>;
			};

			s1-p2@db {
				reg = <0xdb 0x01>;
				bits = <0x02 0x06>;
				phandle = <0x6e>;
			};

			s2-p2@dc {
				reg = <0xdc 0x01>;
				bits = <0x00 0x06>;
				phandle = <0x70>;
			};

			s3-p2@dc {
				reg = <0xdc 0x02>;
				bits = <0x06 0x06>;
				phandle = <0x72>;
			};

			s4-p2@dd {
				reg = <0xdd 0x02>;
				bits = <0x04 0x06>;
				phandle = <0x74>;
			};

			s5-p2@de {
				reg = <0xde 0x02>;
				bits = <0x02 0x06>;
				phandle = <0x76>;
			};

			s6-p2@df {
				reg = <0xdf 0x01>;
				bits = <0x00 0x06>;
				phandle = <0x78>;
			};

			s7-p2@e0 {
				reg = <0xe0 0x01>;
				bits = <0x00 0x06>;
				phandle = <0x7a>;
			};

			s8-p2@e0 {
				reg = <0xe0 0x02>;
				bits = <0x06 0x06>;
				phandle = <0x7c>;
			};

			s9-p2@e1 {
				reg = <0xe1 0x02>;
				bits = <0x04 0x06>;
				phandle = <0x7e>;
			};

			s10-p2@e2 {
				reg = <0xe2 0x02>;
				bits = <0x02 0x06>;
				phandle = <0x80>;
			};

			s5-p2-backup@e3 {
				reg = <0xe3 0x02>;
				bits = <0x00 0x06>;
				phandle = <0x8c>;
			};

			mode-backup@e3 {
				reg = <0xe3 0x01>;
				bits = <0x06 0x02>;
				phandle = <0x68>;
			};

			s6-p2-backup@e4 {
				reg = <0xe4 0x01>;
				bits = <0x00 0x06>;
				phandle = <0x8e>;
			};

			s7-p2-backup@e4 {
				reg = <0xe4 0x02>;
				bits = <0x06 0x06>;
				phandle = <0x90>;
			};

			s8-p2-backup@e5 {
				reg = <0xe5 0x02>;
				bits = <0x04 0x06>;
				phandle = <0x92>;
			};

			s9-p2-backup@e6 {
				reg = <0xe6 0x02>;
				bits = <0x02 0x06>;
				phandle = <0x94>;
			};

			s10-p2-backup@e7 {
				reg = <0xe7 0x01>;
				bits = <0x00 0x06>;
				phandle = <0x96>;
			};

			base1-backup@440 {
				reg = <0x440 0x01>;
				bits = <0x00 0x08>;
				phandle = <0x69>;
			};

			s0-p1-backup@441 {
				reg = <0x441 0x01>;
				bits = <0x00 0x06>;
				phandle = <0x81>;
			};

			s1-p1-backup@442 {
				reg = <0x441 0x02>;
				bits = <0x06 0x06>;
				phandle = <0x83>;
			};

			s2-p1-backup@442 {
				reg = <0x442 0x02>;
				bits = <0x04 0x06>;
				phandle = <0x85>;
			};

			s3-p1-backup@443 {
				reg = <0x443 0x01>;
				bits = <0x02 0x06>;
				phandle = <0x87>;
			};

			s4-p1-backup@444 {
				reg = <0x444 0x01>;
				bits = <0x00 0x06>;
				phandle = <0x89>;
			};

			s5-p1-backup@444 {
				reg = <0x444 0x02>;
				bits = <0x06 0x06>;
				phandle = <0x8b>;
			};

			s6-p1-backup@445 {
				reg = <0x445 0x02>;
				bits = <0x04 0x06>;
				phandle = <0x8d>;
			};

			s7-p1-backup@446 {
				reg = <0x446 0x01>;
				bits = <0x02 0x06>;
				phandle = <0x8f>;
			};

			use-backup@447 {
				reg = <0x447 0x01>;
				bits = <0x05 0x03>;
				phandle = <0x67>;
			};

			s8-p1-backup@448 {
				reg = <0x448 0x01>;
				bits = <0x00 0x06>;
				phandle = <0x91>;
			};

			s9-p1-backup@448 {
				reg = <0x448 0x02>;
				bits = <0x06 0x06>;
				phandle = <0x93>;
			};

			s10-p1-backup@449 {
				reg = <0x449 0x02>;
				bits = <0x04 0x06>;
				phandle = <0x95>;
			};

			base2-backup@44a {
				reg = <0x44a 0x02>;
				bits = <0x02 0x08>;
				phandle = <0x6a>;
			};

			s0-p2-backup@44b {
				reg = <0x44b 0x03>;
				bits = <0x02 0x06>;
				phandle = <0x82>;
			};

			s1-p2-backup@44c {
				reg = <0x44c 0x01>;
				bits = <0x00 0x06>;
				phandle = <0x84>;
			};

			s2-p2-backup@44c {
				reg = <0x44c 0x02>;
				bits = <0x06 0x06>;
				phandle = <0x86>;
			};

			s3-p2-backup@44d {
				reg = <0x44d 0x02>;
				bits = <0x04 0x06>;
				phandle = <0x88>;
			};

			s4-p2-backup@44e {
				reg = <0x44e 0x01>;
				bits = <0x02 0x06>;
				phandle = <0x8a>;
			};
		};

		spmi@fc4cf000 {
			compatible = "qcom,spmi-pmic-arb";
			reg-names = "core\0intr\0cnfg";
			reg = <0xfc4cf000 0x1000 0xfc4cb000 0x1000 0xfc4ca000 0x1000>;
			interrupt-names = "periph_irq";
			interrupts = <0x00 0xbe 0x04>;
			qcom,ee = <0x00>;
			qcom,channel = <0x00>;
			#address-cells = <0x02>;
			#size-cells = <0x00>;
			interrupt-controller;
			#interrupt-cells = <0x04>;

			pm8841@4 {
				compatible = "qcom,pm8841\0qcom,spmi-pmic";
				reg = <0x04 0x00>;
				#address-cells = <0x01>;
				#size-cells = <0x00>;

				mpps@a000 {
					compatible = "qcom,pm8841-mpp\0qcom,spmi-mpp";
					reg = <0xa000>;
					gpio-controller;
					#gpio-cells = <0x02>;
					gpio-ranges = <0x97 0x00 0x00 0x04>;
					interrupt-controller;
					#interrupt-cells = <0x02>;
					phandle = <0x97>;
				};

				temp-alarm@2400 {
					compatible = "qcom,spmi-temp-alarm";
					reg = <0x2400>;
					interrupts = <0x04 0x24 0x00 0x01>;
					#thermal-sensor-cells = <0x00>;
					phandle = <0xbd>;
				};
			};

			pm8841@5 {
				compatible = "qcom,pm8841\0qcom,spmi-pmic";
				reg = <0x05 0x00>;
				#address-cells = <0x01>;
				#size-cells = <0x00>;
			};

			pm8941@0 {
				compatible = "qcom,pm8941\0qcom,spmi-pmic";
				reg = <0x00 0x00>;
				#address-cells = <0x01>;
				#size-cells = <0x00>;

				rtc@6000 {
					compatible = "qcom,pm8941-rtc";
					reg = <0x6000 0x6100>;
					reg-names = "rtc\0alarm";
					interrupts = <0x00 0x61 0x01 0x01>;
				};

				pon@800 {
					compatible = "qcom,pm8941-pon";
					reg = <0x800>;

					pwrkey {
						compatible = "qcom,pm8941-pwrkey";
						interrupts = <0x00 0x08 0x00 0x03>;
						debounce = <0x3d09>;
						bias-pull-up;
					};

					resin {
						compatible = "qcom,pm8941-resin";
						interrupts = <0x00 0x08 0x01 0x03>;
						debounce = <0x3d09>;
						bias-pull-up;
						status = "disabled";
					};
				};

				usb-detect@900 {
					compatible = "qcom,pm8941-misc";
					reg = <0x900>;
					interrupts = <0x00 0x09 0x00 0x03>;
					interrupt-names = "usb_id";
					phandle = <0x3b>;
				};

				charger@1000 {
					compatible = "qcom,pm8941-charger";
					reg = <0x1000>;
					interrupts = <0x00 0x10 0x07 0x03 0x00 0x10 0x05 0x03 0x00 0x10 0x04 0x03 0x00 0x12 0x01 0x03 0x00 0x12 0x00 0x03 0x00 0x13 0x02 0x03 0x00 0x13 0x01 0x03 0x00 0x14 0x01 0x03>;
					interrupt-names = "chg-done\0chg-fast\0chg-trkl\0bat-temp-ok\0bat-present\0chg-gone\0usb-valid\0dc-valid";
					usb-otg-in-supply = <0x98>;
					status = "okay";
					usb-charge-current-limit = <0x16e360>;
					qcom,fast-charge-safe-current = <0x2dc6c0>;
					qcom,fast-charge-current-limit = <0x20ce70>;
					qcom,fast-charge-safe-voltage = <0x432380>;
					qcom,fast-charge-high-threshold-voltage = <0x426030>;
					qcom,auto-recharge-threshold-voltage = <0x414ec0>;
					qcom,minimum-input-voltage = <0x401640>;
					phandle = <0x3a>;

					otg-vbus {
						phandle = <0x3c>;
					};
				};

				gpio@c000 {
					compatible = "qcom,pm8941-gpio\0qcom,spmi-gpio";
					reg = <0xc000>;
					gpio-controller;
					gpio-ranges = <0x99 0x00 0x00 0x24>;
					#gpio-cells = <0x02>;
					interrupt-controller;
					#interrupt-cells = <0x02>;
					phandle = <0x99>;

					boost-bypass-state {
						pins = "gpio21";
						function = "normal";
						phandle = <0xbf>;
					};
				};

				mpps@a000 {
					compatible = "qcom,pm8941-mpp\0qcom,spmi-mpp";
					reg = <0xa000>;
					gpio-controller;
					#gpio-cells = <0x02>;
					gpio-ranges = <0x9a 0x00 0x00 0x08>;
					interrupt-controller;
					#interrupt-cells = <0x02>;
					phandle = <0x9a>;
				};

				temp-alarm@2400 {
					compatible = "qcom,spmi-temp-alarm";
					reg = <0x2400>;
					interrupts = <0x00 0x24 0x00 0x01>;
					io-channels = <0x9b 0x08>;
					io-channel-names = "thermal";
					#thermal-sensor-cells = <0x00>;
					phandle = <0xbe>;
				};

				adc@3100 {
					compatible = "qcom,spmi-vadc";
					reg = <0x3100>;
					interrupts = <0x00 0x31 0x00 0x01>;
					#address-cells = <0x01>;
					#size-cells = <0x00>;
					#io-channel-cells = <0x01>;
					phandle = <0x9b>;

					channel@6 {
						reg = <0x06>;
					};

					channel@8 {
						reg = <0x08>;
					};

					channel@9 {
						reg = <0x09>;
					};

					channel@a {
						reg = <0x0a>;
					};

					channel@e {
						reg = <0x0e>;
					};

					channel@f {
						reg = <0x0f>;
					};

					channel@30 {
						reg = <0x30>;
					};
				};

				adc@3600 {
					compatible = "qcom,pm8941-iadc\0qcom,spmi-iadc";
					reg = <0x3600>;
					interrupts = <0x00 0x36 0x00 0x01>;
					qcom,external-resistor-micro-ohms = <0x2710>;
				};

				charger@2800 {
					compatible = "qcom,pm8941-coincell";
					reg = <0x2800>;
					status = "okay";
					qcom,rset-ohms = <0x320>;
					qcom,vset-millivolts = <0xc80>;
				};

				battery@4000 {
					compatible = "qcom,pm8941-bms";
					reg = <0x4000>;
					interrupts = <0x00 0x40 0x04 0x01>;
					interrupt-names = "ocv_thr";
					io-channels = <0x9b 0x30>;
					io-channel-names = "temp";
					qcom,fcc-temp-legend-celsius = [f6 00 19 32 41];
					qcom,fcc-lut-microamp-hours = <0x314930 0x31be60 0x339320 0x340850 0x334500>;
					qcom,ocv-capacity-legend = [64 5f 5a 55 50 4b 46 41 3c 37 32 2d 28 23 1e 19 14 0f 0a 09 08 07 06 05 04 03 02 01 00];
					qcom,ocv-temp-legend-celsius = [f6 00 19 32 41];
					qcom,ocv-lut-microvolt = <0x41b068 0x41b068 0x41a898 0x4198f8 0x418958 0x414308 0x40f4e8 0x40ed18 0x40dd78 0x408f58 0x405c90 0x400e70 0x400a88 0x3ff700 0x3fa8e0 0x3f7618 0x3f27f8 0x3f3f68 0x3f2be0 0x3eddc0 0x3e9388 0x3e4568 0x3e7060 0x3e64a8 0x3e1688 0x3dc480 0x3d7660 0x3db4e0 0x3dad10 0x3d5ef0 0x3d18a0 0x3cca80 0x3d0ce8 0x3d0130 0x3cb310 0x3c7490 0x3c2670 0x3c5938 0x3c5d20 0x3c0f00 0x3bd468 0x3b8648 0x3ba588 0x3bc0e0 0x3b72c0 0x3b3ff8 0x3af1d8 0x3b1cd0 0x3b3058 0x3ae238 0x3ad298 0x3a8478 0x3aa7a0 0x3aa3b8 0x3a5598 0x3a74d8 0x3a26b8 0x3a5598 0x3a4210 0x39f3f0 0x3a45f8 0x39f7d8 0x3a0b60 0x39fbc0 0x39ada0 0x3a1330 0x39c510 0x39d4b0 0x39bd40 0x396f20 0x39d0c8 0x3982a8 0x39a1e8 0x3976f0 0x3928d0 0x398e60 0x394040 0x394fe0 0x3924e8 0x38d6c8 0x3930a0 0x38e280 0x38e668 0x38d6c8 0x3888a8 0x38d2e0 0x3884c0 0x387cf0 0x387138 0x382318 0x3880d8 0x3832b8 0x380ba8 0x37fff0 0x37b1d0 0x385db0 0x380f90 0x37f438 0x37e880 0x379a60 0x383a88 0x37ec68 0x37d8e0 0x37d4f8 0x3786d8 0x381378 0x37c558 0x37b9a0 0x37c558 0x377738 0x37fc08 0x37ade8 0x3782f0 0x378ac0 0x373ca0 0x37a230 0x375410 0x3734d0 0x371d60 0x36cf40 0x370dc0 0x36bfa0 0x367180 0x3661e0 0x3613c0 0x362f18 0x35e0f8 0x357b68 0x356fb0 0x352190 0x34fe68 0x34b048 0x345670 0x3442e8 0x33f4c8 0x33ae78 0x336058 0x326a40 0x321450 0x31c630 0x2dc6c0 0x2dc6c0 0x2dc6c0 0x2dc6c0 0x2dc6c0>;
					status = "okay";
				};
			};

			pm8941@1 {
				compatible = "qcom,pm8941\0qcom,spmi-pmic";
				reg = <0x01 0x00>;
				#address-cells = <0x01>;
				#size-cells = <0x00>;

				pwm {
					compatible = "qcom,pm8941-lpg";
					#address-cells = <0x01>;
					#size-cells = <0x00>;
					#pwm-cells = <0x02>;
					status = "disabled";
				};

				vibrator@c000 {
					compatible = "qcom,pm8916-vib";
					reg = <0xc000>;
					status = "okay";
				};

				wled@d800 {
					compatible = "qcom,pm8941-wled";
					reg = <0xd800>;
					label = "backlight";
					status = "okay";
					qcom,cs-out;
					qcom,current-limit = <0x17>;
					qcom,current-boost-limit = <0x4ec>;
					qcom,switching-freq = <0x320>;
					qcom,ovp = <0x1d>;
					qcom,num-strings = <0x03>;
					max-brightness = <0xfff>;
					default-brightness = <0x200>;
					phandle = <0xb1>;
				};

				regulators {
					compatible = "qcom,pm8941-regulators";
					interrupts = <0x01 0x83 0x02 0x00 0x01 0x84 0x02 0x00>;
					interrupt-names = "ocp-5vs1\0ocp-5vs2";
					vin_5vs-supply = <0x9c>;

					s4 {
						regulator-min-microvolt = <0x4c4b40>;
						regulator-max-microvolt = <0x4c4b40>;
						regulator-enable-ramp-delay = <0x1f4>;
						phandle = <0x9c>;
					};

					5vs1 {
						regulator-enable-ramp-delay = <0x3e8>;
						regulator-pull-down;
						regulator-over-current-protection;
						qcom,ocp-max-retries = <0x0a>;
						qcom,ocp-retry-delay = <0x1e>;
						qcom,vs-soft-start-strength = <0x00>;
						regulator-initial-mode = <0x01>;
						phandle = <0x98>;
					};

					5vs2 {
						regulator-enable-ramp-delay = <0x3e8>;
						regulator-pull-down;
						regulator-over-current-protection;
						qcom,ocp-max-retries = <0x0a>;
						qcom,ocp-retry-delay = <0x1e>;
						qcom,vs-soft-start-strength = <0x00>;
						regulator-initial-mode = <0x01>;
					};
				};
			};
		};

		dma-controller@fc834000 {
			compatible = "qcom,bam-v1.4.0";
			reg = <0xfc834000 0x7000>;
			interrupts = <0x00 0x1d 0x04>;
			#dma-cells = <0x01>;
			qcom,ee = <0x00>;
			num-channels = <0x06>;
			qcom,num-ees = <0x01>;
			qcom,powered-remotely;
			phandle = <0xa4>;
		};

		remoteproc@fc880000 {
			compatible = "qcom,msm8974-mss-pil";
			reg = <0xfc880000 0x100 0xfc820000 0x20>;
			reg-names = "qdsp6\0rmb";
			interrupts-extended = <0x01 0x00 0x18 0x01 0x9d 0x00 0x01 0x9d 0x01 0x01 0x9d 0x02 0x01 0x9d 0x03 0x01>;
			interrupt-names = "wdog\0fatal\0ready\0handover\0stop-ack";
			clocks = <0x0d 0xb4 0x0d 0xb3 0x0d 0x8b 0x13>;
			clock-names = "iface\0bus\0mem\0xo";
			resets = <0x0d 0x4a>;
			reset-names = "mss_restart";
			power-domains = <0x42 0x00>;
			power-domain-names = "cx";
			qcom,halt-regs = <0x1c 0x1180 0x1200 0x1280>;
			qcom,smem-states = <0x9e 0x00>;
			qcom,smem-state-names = "stop";
			status = "okay";
			mss-supply = <0x9f>;
			mx-supply = <0x44>;
			pll-supply = <0xa0>;

			mba {
				memory-region = <0xa1>;
			};

			mpss {
				memory-region = <0xa2>;
			};

			bam-dmux {
				compatible = "qcom,bam-dmux";
				interrupt-parent = <0xa3>;
				interrupts = <0x01 0x03 0x0b 0x03>;
				interrupt-names = "pc\0pc-ack";
				qcom,smem-states = <0x4a 0x01 0x4a 0x0b>;
				qcom,smem-state-names = "pc\0pc-ack";
				dmas = <0xa4 0x04 0xa4 0x05>;
				dma-names = "tx\0rx";
			};

			smd-edge {
				interrupts = <0x00 0x19 0x01>;
				mboxes = <0x12 0x0c>;
				qcom,smd-edge = <0x00>;
				label = "modem";
			};
		};

		hwlock@fd484000 {
			compatible = "qcom,msm8974-tcsr-mutex\0qcom,tcsr-mutex\0syscon";
			reg = <0xfd484000 0x2000>;
			#hwlock-cells = <0x01>;
			phandle = <0x1c>;
		};

		syscon@fd4a0000 {
			compatible = "qcom,tcsr-msm8974\0syscon";
			reg = <0xfd4a0000 0x10000>;
			phandle = <0x39>;
		};

		pinctrl@fd510000 {
			compatible = "qcom,msm8974-pinctrl";
			reg = <0xfd510000 0x4000>;
			gpio-controller;
			gpio-ranges = <0x26 0x00 0x00 0x92>;
			#gpio-cells = <0x02>;
			interrupt-controller;
			#interrupt-cells = <0x02>;
			interrupts = <0x00 0xd0 0x04>;
			phandle = <0x26>;

			sdc1-off-state {
				phandle = <0x20>;

				clk-pins {
					pins = "sdc1_clk";
					bias-disable;
					drive-strength = <0x02>;
				};

				cmd-pins {
					pins = "sdc1_cmd";
					bias-pull-up;
					drive-strength = <0x02>;
				};

				data-pins {
					pins = "sdc1_data";
					bias-pull-up;
					drive-strength = <0x02>;
				};
			};

			sdc2-off-state {

				clk-pins {
					pins = "sdc2_clk";
					bias-disable;
					drive-strength = <0x02>;
				};

				cmd-pins {
					pins = "sdc2_cmd";
					bias-pull-up;
					drive-strength = <0x02>;
				};

				data-pins {
					pins = "sdc2_data";
					bias-pull-up;
					drive-strength = <0x02>;
				};
			};

			blsp1-uart2-default-state {
				phandle = <0x21>;

				rx-pins {
					pins = "gpio5";
					function = "blsp_uart2";
					drive-strength = <0x02>;
					bias-pull-up;
				};

				tx-pins {
					pins = "gpio4";
					function = "blsp_uart2";
					drive-strength = <0x04>;
					bias-disable;
				};
			};

			blsp2-uart1-default-state {
				phandle = <0x2e>;

				tx-rts-pins {
					pins = "gpio41\0gpio44";
					function = "blsp_uart7";
					drive-strength = <0x02>;
					bias-disable;
				};

				rx-cts-pins {
					pins = "gpio42\0gpio43";
					function = "blsp_uart7";
					drive-strength = <0x02>;
					bias-pull-up;
				};
			};

			blsp2-uart1-sleep-state {
				pins = "gpio41\0gpio42\0gpio43\0gpio44";
				function = "gpio";
				drive-strength = <0x02>;
				bias-pull-down;
				phandle = <0x2f>;
			};

			blsp2-uart4-default-state {
				phandle = <0x30>;

				tx-rts-pins {
					pins = "gpio53\0gpio56";
					function = "blsp_uart10";
					drive-strength = <0x02>;
					bias-disable;
				};

				rx-cts-pins {
					pins = "gpio54\0gpio55";
					function = "blsp_uart10";
					drive-strength = <0x02>;
					bias-pull-up;
				};
			};

			blsp1-i2c1-default-state {
				pins = "gpio2\0gpio3";
				function = "blsp_i2c1";
				drive-strength = <0x02>;
				bias-disable;
				phandle = <0x22>;
			};

			blsp1-i2c1-sleep-state {
				pins = "gpio2\0gpio3";
				function = "blsp_i2c1";
				drive-strength = <0x02>;
				bias-pull-up;
				phandle = <0x23>;
			};

			blsp1-i2c2-default-state {
				pins = "gpio6\0gpio7";
				function = "blsp_i2c2";
				drive-strength = <0x02>;
				bias-disable;
				phandle = <0x24>;
			};

			blsp1-i2c2-sleep-state {
				pins = "gpio6\0gpio7";
				function = "blsp_i2c2";
				drive-strength = <0x02>;
				bias-pull-up;
				phandle = <0x25>;
			};

			blsp1-i2c3-default-state {
				pins = "gpio10\0gpio11";
				function = "blsp_i2c3";
				drive-strength = <0x02>;
				bias-disable;
				phandle = <0x2a>;
			};

			blsp1-i2c3-sleep-state {
				pins = "gpio10\0gpio11";
				function = "blsp_i2c3";
				drive-strength = <0x02>;
				bias-pull-up;
				phandle = <0x2b>;
			};

			blsp1-i2c6-default-state {
				pins = "gpio29\0gpio30";
				function = "blsp_i2c6";
				drive-strength = <0x02>;
				bias-disable;
				phandle = <0x2c>;
			};

			blsp1-i2c6-sleep-state {
				pins = "gpio29\0gpio30";
				function = "blsp_i2c6";
				drive-strength = <0x02>;
				bias-pull-up;
				phandle = <0x2d>;
			};

			blsp2-i2c2-default-state {
				pins = "gpio47\0gpio48";
				function = "blsp_i2c8";
				drive-strength = <0x02>;
				bias-disable;
				phandle = <0x31>;
			};

			blsp2-i2c2-sleep-state {
				pins = "gpio47\0gpio48";
				function = "blsp_i2c8";
				drive-strength = <0x02>;
				bias-pull-up;
				phandle = <0x32>;
			};

			blsp2-i2c5-default-state {
				pins = "gpio83\0gpio84";
				function = "blsp_i2c11";
				drive-strength = <0x02>;
				bias-disable;
				phandle = <0x34>;
			};

			blsp2-i2c5-sleep-state {
				pins = "gpio83\0gpio84";
				function = "blsp_i2c11";
				drive-strength = <0x02>;
				bias-pull-up;
				phandle = <0x35>;
			};

			blsp2-i2c6-default-state {
				pins = "gpio87\0gpio88";
				function = "blsp_i2c12";
				drive-strength = <0x02>;
				bias-disable;
				phandle = <0x36>;
			};

			blsp2-i2c6-sleep-state {
				pins = "gpio87\0gpio88";
				function = "blsp_i2c12";
				drive-strength = <0x02>;
				bias-pull-up;
				phandle = <0x37>;
			};

			cci-default-state {
				phandle = <0xb4>;

				cci-i2c0-default-pins {
					pins = "gpio19\0gpio20";
					function = "cci_i2c0";
					drive-strength = <0x02>;
					bias-disable;
				};

				cci-i2c1-default-pins {
					pins = "gpio21\0gpio22";
					function = "cci_i2c1";
					drive-strength = <0x02>;
					bias-disable;
				};
			};

			cci-sleep-state {
				phandle = <0xb5>;

				cci-i2c0-sleep-pins {
					pins = "gpio19\0gpio20";
					function = "gpio";
					drive-strength = <0x02>;
					bias-disable;
				};

				cci-i2c1-sleep-pins {
					pins = "gpio21\0gpio22";
					function = "gpio";
					drive-strength = <0x02>;
					bias-disable;
				};
			};

			spi8_default-state {

				mosi-pins {
					pins = "gpio45";
					function = "blsp_spi8";
				};

				miso-pins {
					pins = "gpio46";
					function = "blsp_spi8";
				};

				cs-pins {
					pins = "gpio47";
					function = "blsp_spi8";
				};

				clk-pins {
					pins = "gpio48";
					function = "blsp_spi8";
				};
			};

			gpio-hall-sensor-default-state {
				pins = "gpio68";
				function = "gpio";
				drive-strength = <0x08>;
				bias-pull-up;
			};

			sdc1-on-state {
				phandle = <0x1f>;

				clk-pins {
					pins = "sdc1_clk";
					drive-strength = <0x04>;
					bias-disable;
				};

				cmd-data-pins {
					pins = "sdc1_cmd\0sdc1_data";
					drive-strength = <0x04>;
					bias-pull-up;
				};
			};

			panel-te-state {
				pins = "gpio12";
				function = "mdp_vsync";
				drive-strength = <0x02>;
				bias-disable;
				phandle = <0xb0>;
			};

			touchscreen-int-state {
				pins = "gpio54";
				function = "gpio";
				bias-pull-up;
				drive-strength = <0x02>;
				phandle = <0x27>;
			};

			wcnss-pin-active-state {
				phandle = <0x45>;

				bt-pins {
					pins = "gpio35\0gpio43\0gpio44";
					function = "bt";
					drive-strength = <0x02>;
					bias-pull-down;
				};

				wlan-pins {
					pins = "gpio36\0gpio37\0gpio38\0gpio39\0gpio40";
					function = "wlan";
					drive-strength = <0x06>;
					bias-pull-down;
				};
			};
		};

		clock-controller@fd8c0000 {
			compatible = "qcom,mmcc-msm8974";
			#clock-cells = <0x01>;
			#reset-cells = <0x01>;
			#power-domain-cells = <0x01>;
			reg = <0xfd8c0000 0x6000>;
			clocks = <0x13 0x0d 0x110 0x0d 0x01 0x0d 0x0d 0x46 0x20 0xa5 0x01 0xa5 0x00 0xa6 0x01 0xa6 0x00 0x00 0x00 0x00>;
			clock-names = "xo\0mmss_gpll0_vote\0gpll0_vote\0gpll1_vote\0gfx3d_clk_src\0dsi0pll\0dsi0pllbyte\0dsi1pll\0dsi1pllbyte\0hdmipll\0edp_link_clk\0edp_vco_div";
			phandle = <0x63>;
		};

		display-subsystem@fd900000 {
			compatible = "qcom,mdss";
			reg = <0xfd900000 0x100 0xfd924000 0x1000>;
			reg-names = "mdss_phys\0vbif_phys";
			power-domains = <0x63 0x01>;
			clocks = <0x63 0x5d 0x63 0x5e 0x63 0x6d>;
			clock-names = "iface\0bus\0vsync";
			interrupts = <0x00 0x48 0x04>;
			interrupt-controller;
			#interrupt-cells = <0x01>;
			status = "okay";
			#address-cells = <0x01>;
			#size-cells = <0x01>;
			ranges;
			phandle = <0xa7>;

			display-controller@fd900000 {
				compatible = "qcom,msm8974-mdp5\0qcom,mdp5";
				reg = <0xfd900100 0x22000>;
				reg-names = "mdp_phys";
				interrupt-parent = <0xa7>;
				interrupts = <0x00>;
				clocks = <0x63 0x5d 0x63 0x5e 0x63 0x69 0x63 0x6d>;
				clock-names = "iface\0bus\0core\0vsync";
				interconnects = <0xa8 0x02 0xa9 0x05>;
				interconnect-names = "mdp0-mem";

				ports {
					#address-cells = <0x01>;
					#size-cells = <0x00>;

					port@0 {
						reg = <0x00>;

						endpoint {
							remote-endpoint = <0xaa>;
							phandle = <0xae>;
						};
					};

					port@1 {
						reg = <0x01>;

						endpoint {
							remote-endpoint = <0xab>;
							phandle = <0xb3>;
						};
					};
				};
			};

			dsi@fd922800 {
				compatible = "qcom,msm8974-dsi-ctrl\0qcom,mdss-dsi-ctrl";
				reg = <0xfd922800 0x1f8>;
				reg-names = "dsi_ctrl";
				interrupt-parent = <0xa7>;
				interrupts = <0x04>;
				assigned-clocks = <0x63 0x21 0x63 0x13>;
				assigned-clock-parents = <0xa5 0x00 0xa5 0x01>;
				clocks = <0x63 0x69 0x63 0x5d 0x63 0x5e 0x63 0x5f 0x63 0x6b 0x63 0x64 0x63 0x6e>;
				clock-names = "mdp_core\0iface\0bus\0byte\0pixel\0core\0core_mmss";
				phys = <0xa5>;
				status = "okay";
				#address-cells = <0x01>;
				#size-cells = <0x00>;
				vdda-supply = <0xac>;
				vdd-supply = <0xad>;
				vddio-supply = <0xa0>;

				ports {
					#address-cells = <0x01>;
					#size-cells = <0x00>;

					port@0 {
						reg = <0x00>;

						endpoint {
							remote-endpoint = <0xae>;
							phandle = <0xaa>;
						};
					};

					port@1 {
						reg = <0x01>;

						endpoint {
							remote-endpoint = <0xaf>;
							data-lanes = <0x00 0x01 0x02 0x03>;
							phandle = <0xb2>;
						};
					};
				};

				panel@0 {
					reg = <0x00>;
					compatible = "xiaomi,cancro-panel";
					reset-gpios = <0x99 0x13 0x01>;
					pinctrl-names = "default";
					pinctrl-0 = <0xb0>;
					backlight = <0xb1>;

					port {

						endpoint {
							remote-endpoint = <0xb2>;
							phandle = <0xaf>;
						};
					};
				};
			};

			phy@fd922a00 {
				compatible = "qcom,dsi-phy-28nm-hpm";
				reg = <0xfd922a00 0xd4 0xfd922b00 0x280 0xfd922d80 0x30>;
				reg-names = "dsi_pll\0dsi_phy\0dsi_phy_regulator";
				#clock-cells = <0x01>;
				#phy-cells = <0x00>;
				clocks = <0x63 0x5d 0x13>;
				clock-names = "iface\0ref";
				status = "okay";
				vddio-supply = <0xa0>;
				phandle = <0xa5>;
			};

			dsi@fd922e00 {
				compatible = "qcom,msm8974-dsi-ctrl\0qcom,mdss-dsi-ctrl";
				reg = <0xfd922e00 0x1f8>;
				reg-names = "dsi_ctrl";
				interrupt-parent = <0xa7>;
				interrupts = <0x04>;
				assigned-clocks = <0x63 0x22 0x63 0x14>;
				assigned-clock-parents = <0xa6 0x00 0xa6 0x01>;
				clocks = <0x63 0x69 0x63 0x5d 0x63 0x5e 0x63 0x60 0x63 0x6c 0x63 0x65 0x63 0x6e>;
				clock-names = "mdp_core\0iface\0bus\0byte\0pixel\0core\0core_mmss";
				phys = <0xa6>;
				status = "disabled";
				#address-cells = <0x01>;
				#size-cells = <0x00>;

				ports {
					#address-cells = <0x01>;
					#size-cells = <0x00>;

					port@0 {
						reg = <0x00>;

						endpoint {
							remote-endpoint = <0xb3>;
							phandle = <0xab>;
						};
					};

					port@1 {
						reg = <0x01>;

						endpoint {
						};
					};
				};
			};

			phy@fd923000 {
				compatible = "qcom,dsi-phy-28nm-hpm";
				reg = <0xfd923000 0xd4 0xfd923100 0x280 0xfd923380 0x30>;
				reg-names = "dsi_pll\0dsi_phy\0dsi_phy_regulator";
				#clock-cells = <0x01>;
				#phy-cells = <0x00>;
				clocks = <0x63 0x5d 0x13>;
				clock-names = "iface\0ref";
				status = "disabled";
				phandle = <0xa6>;
			};
		};

		cci@fda0c000 {
			compatible = "qcom,msm8974-cci";
			#address-cells = <0x01>;
			#size-cells = <0x00>;
			reg = <0xfda0c000 0x1000>;
			interrupts = <0x00 0x32 0x01>;
			clocks = <0x63 0x55 0x63 0x2c 0x63 0x2d>;
			clock-names = "camss_top_ahb\0cci_ahb\0cci";
			pinctrl-names = "default\0sleep";
			pinctrl-0 = <0xb4>;
			pinctrl-1 = <0xb5>;
			status = "disabled";

			i2c-bus@0 {
				reg = <0x00>;
				clock-frequency = <0x186a0>;
				#address-cells = <0x01>;
				#size-cells = <0x00>;
			};

			i2c-bus@1 {
				reg = <0x01>;
				clock-frequency = <0x186a0>;
				#address-cells = <0x01>;
				#size-cells = <0x00>;
			};
		};

		gpu@fdb00000 {
			compatible = "qcom,adreno-330.2\0qcom,adreno";
			reg = <0xfdb00000 0x10000>;
			reg-names = "kgsl_3d0_reg_memory";
			interrupts = <0x00 0x21 0x04>;
			interrupt-names = "kgsl_3d0_irq";
			clocks = <0x63 0x77 0x63 0x78 0x63 0x79>;
			clock-names = "core\0iface\0mem_iface";
			sram = <0xb6>;
			power-domains = <0x63 0x05>;
			operating-points-v2 = <0xb7>;
			interconnects = <0xa8 0x00 0xa9 0x05 0xb8 0x0a 0xb8 0x0b>;
			interconnect-names = "gfx-mem\0ocmem";
			status = "okay";

			opp-table {
				compatible = "operating-points-v2";
				phandle = <0xb7>;

				opp-320000000 {
					opp-hz = <0x00 0x1312d000>;
				};

				opp-200000000 {
					opp-hz = <0x00 0xbebc200>;
				};

				opp-27000000 {
					opp-hz = <0x00 0x19bfcc0>;
				};
			};
		};

		sram@fdd00000 {
			compatible = "qcom,msm8974-ocmem";
			reg = <0xfdd00000 0x2000 0xfec00000 0x180000>;
			reg-names = "ctrl\0mem";
			ranges = <0x00 0xfec00000 0x180000>;
			clocks = <0x46 0x22 0x63 0x74>;
			clock-names = "core\0iface";
			#address-cells = <0x01>;
			#size-cells = <0x01>;

			gmu-sram@0 {
				reg = <0x00 0x100000>;
				phandle = <0xb6>;
			};
		};

		remoteproc@fe200000 {
			compatible = "qcom,msm8974-adsp-pil";
			reg = <0xfe200000 0x100>;
			interrupts-extended = <0x01 0x00 0xa2 0x01 0xb9 0x00 0x01 0xb9 0x01 0x01 0xb9 0x02 0x01 0xb9 0x03 0x01>;
			interrupt-names = "wdog\0fatal\0ready\0handover\0stop-ack";
			clocks = <0x13>;
			clock-names = "xo";
			power-domains = <0x42 0x00>;
			power-domain-names = "cx";
			memory-region = <0xba>;
			qcom,smem-states = <0xbb 0x00>;
			qcom,smem-state-names = "stop";
			status = "okay";

			smd-edge {
				interrupts = <0x00 0x9c 0x01>;
				mboxes = <0x12 0x08>;
				qcom,smd-edge = <0x01>;
				label = "lpass";

				apr {
					#size-cells = <0x00>;
					#address-cells = <0x01>;
					qcom,domain = <0x04>;
					qcom,smd-channels = "apr_audio_svc";
					compatible = "qcom,apr-v2";

					service@8 {
						reg = <0x08>;
						compatible = "qcom,q6adm";

						routing {
							phandle = <0xc4>;
							#sound-dai-cells = <0x00>;
							compatible = "qcom,q6adm-routing";
						};
					};

					service@7 {
						reg = <0x07>;
						compatible = "qcom,q6asm";

						dais {
							phandle = <0xc2>;
							#sound-dai-cells = <0x01>;
							#size-cells = <0x00>;
							#address-cells = <0x01>;
							compatible = "qcom,q6asm-dais";

							dai@0 {
								direction = <0x02>;
								reg = <0x00>;
							};
						};
					};

					service@4 {
						reg = <0x04>;
						compatible = "qcom,q6afe";

						dais {
							phandle = <0xc3>;
							#sound-dai-cells = <0x01>;
							#size-cells = <0x00>;
							#address-cells = <0x01>;
							compatible = "qcom,q6afe-dais";

							dai@2 {
								reg = <0x02>;
							};
						};
					};

					service@3 {
						reg = <0x03>;
						compatible = "qcom,q6core";
					};
				};
			};
		};

		sram@fe805000 {
			compatible = "qcom,msm8974-imem\0syscon\0simple-mfd";
			reg = <0xfe805000 0x1000>;

			reboot-mode {
				compatible = "syscon-reboot-mode";
				offset = <0x65c>;
			};
		};
	};

	thermal-zones {

		cpu0-thermal {
			polling-delay-passive = <0xfa>;
			polling-delay = <0x3e8>;
			thermal-sensors = <0xbc 0x05>;

			trips {

				trip0 {
					temperature = <0x124f8>;
					hysteresis = <0x7d0>;
					type = "passive";
				};

				trip1 {
					temperature = <0x1adb0>;
					hysteresis = <0x7d0>;
					type = "critical";
				};
			};
		};

		cpu1-thermal {
			polling-delay-passive = <0xfa>;
			polling-delay = <0x3e8>;
			thermal-sensors = <0xbc 0x06>;

			trips {

				trip0 {
					temperature = <0x124f8>;
					hysteresis = <0x7d0>;
					type = "passive";
				};

				trip1 {
					temperature = <0x1adb0>;
					hysteresis = <0x7d0>;
					type = "critical";
				};
			};
		};

		cpu2-thermal {
			polling-delay-passive = <0xfa>;
			polling-delay = <0x3e8>;
			thermal-sensors = <0xbc 0x07>;

			trips {

				trip0 {
					temperature = <0x124f8>;
					hysteresis = <0x7d0>;
					type = "passive";
				};

				trip1 {
					temperature = <0x1adb0>;
					hysteresis = <0x7d0>;
					type = "critical";
				};
			};
		};

		cpu3-thermal {
			polling-delay-passive = <0xfa>;
			polling-delay = <0x3e8>;
			thermal-sensors = <0xbc 0x08>;

			trips {

				trip0 {
					temperature = <0x124f8>;
					hysteresis = <0x7d0>;
					type = "passive";
				};

				trip1 {
					temperature = <0x1adb0>;
					hysteresis = <0x7d0>;
					type = "critical";
				};
			};
		};

		q6-dsp-thermal {
			polling-delay-passive = <0xfa>;
			polling-delay = <0x3e8>;
			thermal-sensors = <0xbc 0x01>;

			trips {

				trip-point0 {
					temperature = <0x15f90>;
					hysteresis = <0x7d0>;
					type = "hot";
				};
			};
		};

		modemtx-thermal {
			polling-delay-passive = <0xfa>;
			polling-delay = <0x3e8>;
			thermal-sensors = <0xbc 0x02>;

			trips {

				trip-point0 {
					temperature = <0x15f90>;
					hysteresis = <0x7d0>;
					type = "hot";
				};
			};
		};

		video-thermal {
			polling-delay-passive = <0xfa>;
			polling-delay = <0x3e8>;
			thermal-sensors = <0xbc 0x03>;

			trips {

				trip-point0 {
					temperature = <0x17318>;
					hysteresis = <0x7d0>;
					type = "hot";
				};
			};
		};

		wlan-thermal {
			polling-delay-passive = <0xfa>;
			polling-delay = <0x3e8>;
			thermal-sensors = <0xbc 0x04>;

			trips {

				trip-point0 {
					temperature = <0x19a28>;
					hysteresis = <0x7d0>;
					type = "hot";
				};
			};
		};

		gpu-top-thermal {
			polling-delay-passive = <0xfa>;
			polling-delay = <0x3e8>;
			thermal-sensors = <0xbc 0x09>;

			trips {

				trip-point0 {
					temperature = <0x15f90>;
					hysteresis = <0x7d0>;
					type = "hot";
				};
			};
		};

		gpu-bottom-thermal {
			polling-delay-passive = <0xfa>;
			polling-delay = <0x3e8>;
			thermal-sensors = <0xbc 0x0a>;

			trips {

				trip-point0 {
					temperature = <0x15f90>;
					hysteresis = <0x7d0>;
					type = "hot";
				};
			};
		};

		pm8841-thermal {
			polling-delay-passive = <0x64>;
			polling-delay = <0x00>;
			thermal-sensors = <0xbd>;

			trips {

				trip0 {
					temperature = <0x19a28>;
					hysteresis = <0x7d0>;
					type = "passive";
				};

				trip1 {
					temperature = <0x1e848>;
					hysteresis = <0x7d0>;
					type = "hot";
				};

				crit {
					temperature = <0x222e0>;
					hysteresis = <0x7d0>;
					type = "critical";
				};
			};
		};

		pm8941-thermal {
			polling-delay-passive = <0x64>;
			polling-delay = <0x00>;
			thermal-sensors = <0xbe>;

			trips {

				trip0 {
					temperature = <0x19a28>;
					hysteresis = <0x7d0>;
					type = "passive";
				};

				trip1 {
					temperature = <0x1e848>;
					hysteresis = <0x7d0>;
					type = "hot";
				};

				crit {
					temperature = <0x23668>;
					hysteresis = <0x7d0>;
					type = "critical";
				};
			};
		};
	};

	timer {
		compatible = "arm,armv7-timer";
		interrupts = <0x01 0x02 0xf08 0x01 0x03 0xf08 0x01 0x04 0xf08 0x01 0x01 0xf08>;
		clock-frequency = <0x124f800>;
	};

	aliases {
		mmc0 = "/soc/mmc@f9824900";
		serial0 = "/soc/serial@f991e000";
	};

	vreg-boost {
		compatible = "regulator-fixed";
		regulator-name = "vreg-boost";
		regulator-min-microvolt = <0x3010b0>;
		regulator-max-microvolt = <0x3010b0>;
		regulator-always-on;
		regulator-boot-on;
		gpio = <0x99 0x15 0x00>;
		enable-active-high;
		pinctrl-names = "default";
		pinctrl-0 = <0xbf>;
		phandle = <0x19>;
	};

	vreg-tp-power-3p2 {
		compatible = "regulator-fixed";
		regulator-name = "vreg_tp_power_3p2";
		regulator-min-microvolt = <0x30d400>;
		regulator-max-microvolt = <0x30d400>;
		gpio = <0x26 0x1b 0x00>;
		enable-active-high;
		regulator-always-on;
		phandle = <0x29>;
	};

	vreg-tp-power-1p8 {
		compatible = "regulator-fixed";
		regulator-name = "vreg_tp_power_1p8";
		regulator-min-microvolt = <0x1b7740>;
		regulator-max-microvolt = <0x1b7740>;
		gpio = <0x26 0x30 0x00>;
		enable-active-high;
		regulator-always-on;
		phandle = <0x28>;
	};

	vreg-vph-pwr {
		compatible = "regulator-fixed";
		regulator-name = "vph-pwr";
		regulator-min-microvolt = <0x36ee80>;
		regulator-max-microvolt = <0x36ee80>;
		regulator-always-on;
		phandle = <0x18>;
	};
};
